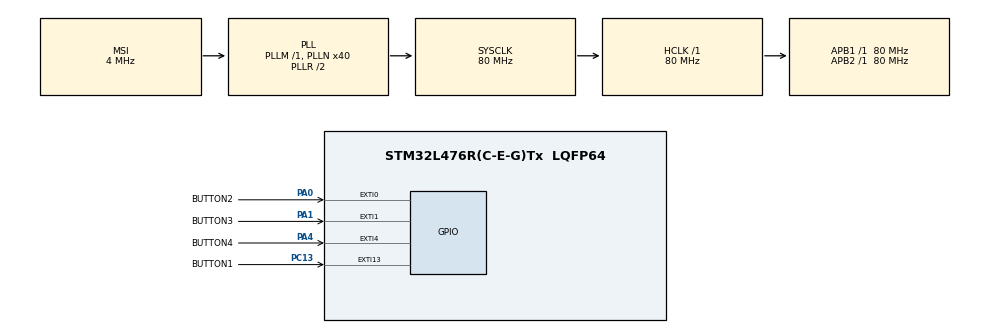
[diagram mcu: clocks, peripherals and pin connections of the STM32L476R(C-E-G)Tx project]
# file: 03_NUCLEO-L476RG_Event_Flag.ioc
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Mcu.Family=STM32L4
Mcu.Name=STM32L476R(C-E-G)Tx
Mcu.Package=LQFP64
Mcu.UserConstants=TIMER_PRESCALER,7999;TIMER_COUNTER,9
NVIC.EXTI0_IRQn=true\:0\:0\:false\:false\:true\:true\:true
NVIC.EXTI15_10_IRQn=true\:0\:0\:false\:false\:true\:true\:true
NVIC.EXTI1_IRQn=true\:0\:0\:false\:false\:true\:true\:true
NVIC.EXTI4_IRQn=true\:0\:0\:false\:false\:true\:true\:true
NVIC.PriorityGroup=NVIC_PRIORITYGROUP_4
NVIC.TIM6_DAC_IRQn=true\:0\:0\:false\:false\:true\:true\:true
PA0.GPIO_Label=BUTTON2
PA0.GPIO_ModeDefaultEXTI=GPIO_MODE_IT_FALLING
PA0.GPIO_PuPd=GPIO_PULLUP
PA0.Signal=GPXTI0
PA1.GPIO_Label=BUTTON3
PA1.GPIO_ModeDefaultEXTI=GPIO_MODE_IT_FALLING
PA1.GPIO_PuPd=GPIO_PULLUP
PA1.Signal=GPXTI1
PA4.GPIO_Label=BUTTON4
PA4.GPIO_ModeDefaultEXTI=GPIO_MODE_IT_FALLING
PA4.GPIO_PuPd=GPIO_PULLUP
PA4.Signal=GPXTI4
PC13.GPIO_Label=BUTTON1
PC13.GPIO_ModeDefaultEXTI=GPIO_MODE_IT_FALLING
PC13.GPIO_PuPd=GPIO_PULLUP
PC13.Signal=GPXTI13
ProjectManager.HeapSize=0x200
ProjectManager.StackSize=0x400
ProjectManager.TargetToolchain=STM32CubeIDE
RCC.AHBFreq_Value=80000000
RCC.APB1Freq_Value=80000000
RCC.APB1TimFreq_Value=80000000
RCC.APB2Freq_Value=80000000
RCC.APB2TimFreq_Value=80000000
RCC.CortexFreq_Value=80000000
RCC.HCLKFreq_Value=80000000
RCC.HSE_VALUE=8000000
RCC.HSI_VALUE=16000000
RCC.LSE_VALUE=32768
RCC.MSI_VALUE=4000000
RCC.PLLN=40
RCC.SYSCLKFreq_VALUE=80000000
RCC.SYSCLKSource=RCC_SYSCLKSOURCE_PLLCLK
RCC.VCOOutputFreq_Value=160000000
TIM6.Period=TIMER_COUNTER
TIM6.Prescaler=TIMER_PRESCALER
VP_TIM6_VS_ClockSourceINT.Mode=Enable_Timer
board=custom

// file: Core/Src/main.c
/* USER CODE BEGIN Header */
/**
  ******************************************************************************
  * @file           : main.c
  * @brief          : Main program body
  ******************************************************************************
  * @attention
  *
  * <h2><center>&copy; Copyright (c) 2020 STMicroelectronics.
  * All rights reserved.</center></h2>
  *
  * This software component is licensed by ST under BSD 3-Clause license,
  * the "License"; You may not use this file except in compliance with the
  * License. You may obtain a copy of the License at:
  *                        opensource.org/licenses/BSD-3-Clause
  *
  ******************************************************************************
  */
/* USER CODE END Header */

#include "main.h"
#include "tim.h"
#include "gpio.h"

/* USER CODE BEGIN Includes */
#include "event_flag.h"

/* USER CODE END Includes */

void SystemClock_Config(void);

int main(void)
{

  /* MCU Configuration--------------------------------------------------------*/

  /* Reset of all peripherals, Initializes the Flash interface and the Systick. */
  HAL_Init();

  /* Configure the system clock */
  SystemClock_Config();

  /* Initialize all configured peripherals */
  MX_GPIO_Init();
  MX_TIM6_Init();

  /* Infinite loop */
  /* USER CODE BEGIN WHILE */
  while (1)
  {
	  MainLoop();
    /* USER CODE END WHILE */

  }
}

void SystemClock_Config(void)
{
  RCC_OscInitTypeDef RCC_OscInitStruct = {0};
  RCC_ClkInitTypeDef RCC_ClkInitStruct = {0};

  /** Initializes the CPU, AHB and APB busses clocks
  */
  RCC_OscInitStruct.OscillatorType = RCC_OSCILLATORTYPE_MSI;
  RCC_OscInitStruct.MSIState = RCC_MSI_ON;
  RCC_OscInitStruct.MSICalibrationValue = 0;
  RCC_OscInitStruct.MSIClockRange = RCC_MSIRANGE_6;
  RCC_OscInitStruct.PLL.PLLState = RCC_PLL_ON;
  RCC_OscInitStruct.PLL.PLLSource = RCC_PLLSOURCE_MSI;
  RCC_OscInitStruct.PLL.PLLM = 1;
  RCC_OscInitStruct.PLL.PLLN = 40;
  RCC_OscInitStruct.PLL.PLLP = RCC_PLLP_DIV7;
  RCC_OscInitStruct.PLL.PLLQ = RCC_PLLQ_DIV2;
  RCC_OscInitStruct.PLL.PLLR = RCC_PLLR_DIV2;
  if (HAL_RCC_OscConfig(&RCC_OscInitStruct) != HAL_OK)
  {
    Error_Handler();
  }
  /** Initializes the CPU, AHB and APB busses clocks
  */
  RCC_ClkInitStruct.ClockType = RCC_CLOCKTYPE_HCLK|RCC_CLOCKTYPE_SYSCLK
                              |RCC_CLOCKTYPE_PCLK1|RCC_CLOCKTYPE_PCLK2;
  RCC_ClkInitStruct.SYSCLKSource = RCC_SYSCLKSOURCE_PLLCLK;
  RCC_ClkInitStruct.AHBCLKDivider = RCC_SYSCLK_DIV1;
  RCC_ClkInitStruct.APB1CLKDivider = RCC_HCLK_DIV1;
  RCC_ClkInitStruct.APB2CLKDivider = RCC_HCLK_DIV1;

  if (HAL_RCC_ClockConfig(&RCC_ClkInitStruct, FLASH_LATENCY_4) != HAL_OK)
  {
    Error_Handler();
  }
  /** Configure the main internal regulator output voltage
  */
  if (HAL_PWREx_ControlVoltageScaling(PWR_REGULATOR_VOLTAGE_SCALE1) != HAL_OK)
  {
    Error_Handler();
  }
}

void Error_Handler(void)
{
}

/************************ (C) COPYRIGHT STMicroelectronics *****END OF FILE****/
